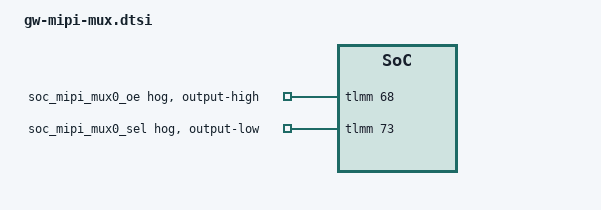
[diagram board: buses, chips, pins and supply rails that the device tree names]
// MIPI Mux GPIOs

&tlmm {
  soc_mipi_mux0_oe: soc_mipi_mux0_oe {
    gpio-hog;
    gpios = <68 GPIO_ACTIVE_HIGH>;
    output-high;
  };
  soc_mipi_mux0_sel: soc_mipi_mux0_sel {
    gpio-hog;
    gpios = <73 GPIO_ACTIVE_HIGH>;
    output-low;
  };
};
